# apollo2 register map
Vendor: Ambiq Micro; Series: Apollo; File version: 1.0
CPU: CM4 r1p0, little endian, MPU, FPU, 3 interrupt priority bits
Registers are 32-bit, read-write, reset 0x0 unless marked. A register's access mark holds for its fields unless they carry their own. Offsets are from the block's base; [hi:lo] are bit positions; 'fields as' and 'values as' point back to an identical list.

## RTC — Real Time Clock
Base 0x40004040
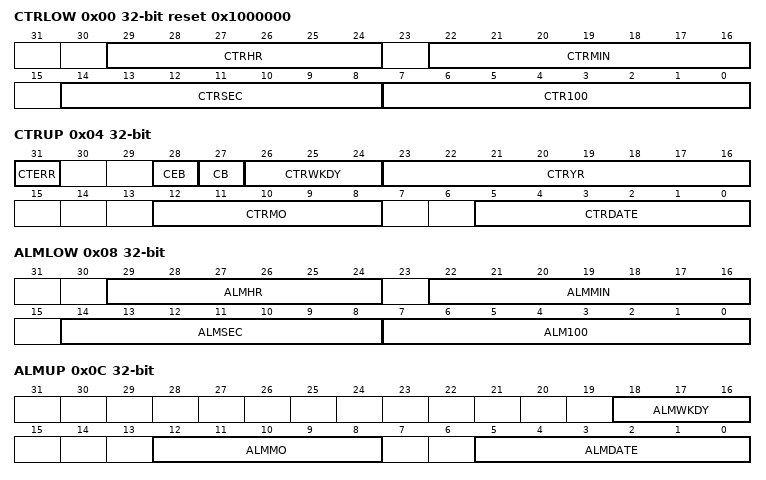
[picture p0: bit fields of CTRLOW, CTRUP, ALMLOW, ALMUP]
0x00 CTRLOW reset 0x1000000 — RTC Counters Lower
  [29:24] CTRHR — Hours Counter
  [22:16] CTRMIN — Minutes Counter
  [14:8] CTRSEC — Seconds Counter
  [7:0] CTR100 — 100ths of a second Counter
0x04 CTRUP — RTC Counters Upper
  [31] CTERR — Counter read error status
    0=NOERR (No read error occurred value.); 1=RDERR (Read error occurred value.)
  [28] CEB — Century enable
    0=DIS (Disable the Century bit from changing value.); 1=EN (Enable the Century bit to change value.)
  [27] CB — Century
    0=Century is 2000s value; 1=1900_2100 (Century is 1900s/2100s value.)
  [26:24] CTRWKDY — Weekdays Counter
  [23:16] CTRYR — Years Counter
  [12:8] CTRMO — Months Counter
  [5:0] CTRDATE — Date Counter
0x08 ALMLOW — RTC Alarms Lower
  [29:24] ALMHR — Hours Alarm
  [22:16] ALMMIN — Minutes Alarm
  [14:8] ALMSEC — Seconds Alarm
  [7:0] ALM100 — 100ths of a second Alarm
0x0C ALMUP — RTC Alarms Upper
  [18:16] ALMWKDY — Weekdays Alarm
  [12:8] ALMMO — Months Alarm
  [5:0] ALMDATE — Date Alarm
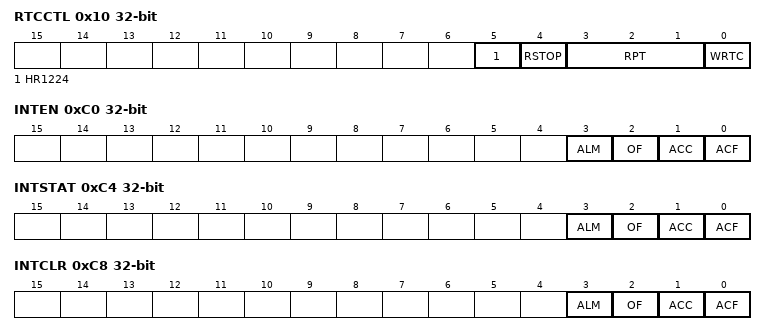
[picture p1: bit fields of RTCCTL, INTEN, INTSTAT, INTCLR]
0x10 RTCCTL — RTC Control Register
  [5] HR1224 — Hours Counter mode
    0=24HR (Hours in 24 hour mode value.); 1=12HR (Hours in 12 hour mode value.)
  [4] RSTOP — RTC input clock control
    0=RUN (Allow the RTC input clock to run value.); 1=STOP (Stop the RTC input clock value.)
  [3:1] RPT — Alarm repeat interval
    0=DIS (Alarm interrupt disabled value.); 1=YEAR (Interrupt every year value.); 2=MONTH (Interrupt every month value.); 3=WEEK (Interrupt every week value.); 4=DAY (Interrupt every day value.); 5=HR (Interrupt every hour value.); 6=MIN (Interrupt every minute value.); 7=SEC (Interrupt every second/10th/100th value.)
  [0] WRTC — Counter write control
    0=DIS (Counter writes are disabled value.); 1=EN (Counter writes are enabled value.)
0xC0 INTEN — RTC Interrupt Register: Enable
  [3] ALM — RTC Alarm interrupt
  [2] OF — XT Oscillator Fail interrupt
  [1] ACC — Autocalibration Complete interrupt
  [0] ACF — Autocalibration Fail interrupt
0xC4 INTSTAT — RTC Interrupt Register: Status
  fields as INTEN
0xC8 INTCLR — RTC Interrupt Register: Clear
  fields as INTEN
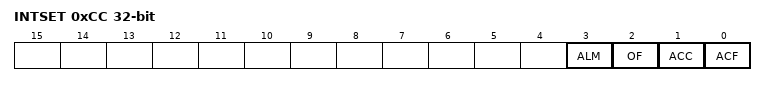
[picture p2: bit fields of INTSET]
0xCC INTSET — RTC Interrupt Register: Set
  fields as INTEN

## VCOMP — Voltage Comparator
Base 0x4000C000
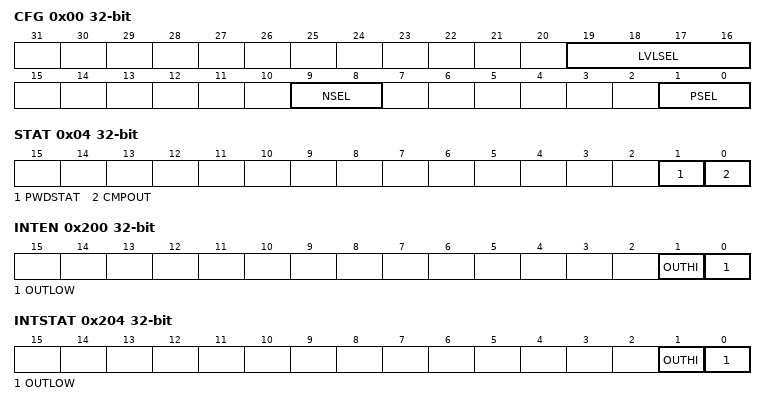
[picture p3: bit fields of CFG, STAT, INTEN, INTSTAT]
0x00 CFG — Configuration Register
  [19:16] LVLSEL — When the reference input NSEL is set to NSEL_DAC, this bitfield selects the voltage level for the negative input to the comparator.
    0=0P58V (Set Reference input to 0.58 Volts. value.); 1=0P77V (Set Reference input to 0.77 Volts. value.); 2=0P97V (Set Reference input to 0.97 Volts. value.); 3=1P16V (Set Reference input to 1.16 Volts. value.); 4=1P35V (Set Reference input to 1.35 Volts. value.); 5=1P55V (Set Reference input to 1.55 Volts. value.); 6=1P74V (Set Reference input to 1.74 Volts. value.); 7=1P93V (Set Reference input to 1.93 Volts. value.); 8=2P13V (Set Reference input to 2.13 Volts. value.); 9=2P32V (Set Reference input to 2.32 Volts. value.); 10=2P51V (Set Reference input to 2.51 Volts. value.); 11=2P71V (Set Reference input to 2.71 Volts. value.); 12=2P90V (Set Reference input to 2.90 Volts. value.); 13=3P09V (Set Reference input to 3.09 Volts. value.); 14=3P29V (Set Reference input to 3.29 Volts. value.); 15=3P48V (Set Reference input to 3.48 Volts. value.)
  [9:8] NSEL — This bitfield selects the negative input to the comparator.
    0=VREFEXT1 (Use external reference 1 for reference input. value.); 1=VREFEXT2 (Use external reference 2 for reference input. value.); 2=VREFEXT3 (Use external reference 3 for reference input. value.); 3=DAC (Use DAC output selected by LVLSEL for reference input. value.)
  [1:0] PSEL — This bitfield selects the positive input to the comparator.
    0=VDDADJ (Use VDDADJ for the positive input. value.); 1=VTEMP (Use the temperature sensor output for the positive input. Note: If this channel is selected for PSEL, the bandap circuit required for temperature comparisons will automatically turn on. The bandgap circuit requires 11us to stabalize. value.); 2=VEXT1 (Use external voltage 0 for positive input. value.); 3=VEXT2 (Use external voltage 1 for positive input. value.)
0x04 STAT — Status Register
  [1] PWDSTAT — This bit indicates the power down state of the voltage comparator.
    1=POWERED_DOWN (The voltage comparator is powered down. value.)
  [0] CMPOUT — This bit is 1 if the positive input of the comparator is greater than the negative input.
    0=VOUT_LOW (The negative input of the comparator is greater than the positive input. value.); 1=VOUT_HIGH (The positive input of the comparator is greater than the negative input. value.)
0x08 PWDKEY — Key Register for Powering Down the Voltage Comparator
  [31:0] PWDKEY — Key register value.
    55=Key (Key value.)
0x200 INTEN — Voltage Comparator Interrupt registers: Enable
  [1] OUTHI — This bit is the vcompout high interrupt.
  [0] OUTLOW — This bit is the vcompout low interrupt.
0x204 INTSTAT — Voltage Comparator Interrupt registers: Status
  fields as INTEN
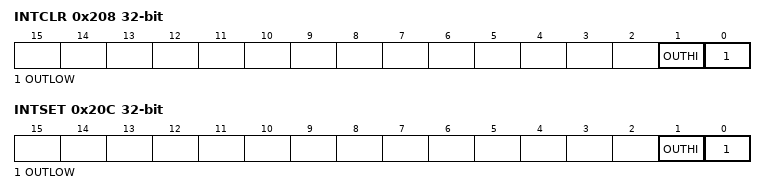
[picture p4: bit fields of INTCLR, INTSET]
0x208 INTCLR — Voltage Comparator Interrupt registers: Clear
  fields as INTEN
0x20C INTSET — Voltage Comparator Interrupt registers: Set
  fields as INTEN

## WDT — Watchdog Timer
Base 0x40024000
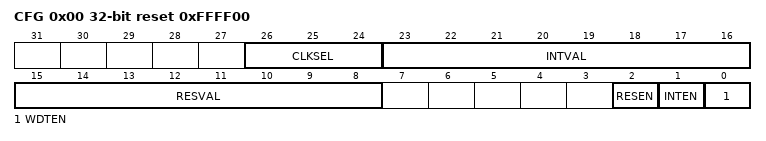
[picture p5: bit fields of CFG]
0x00 CFG reset 0xFFFF00 — Configuration Register
  [26:24] CLKSEL — Select the frequency for the WDT. All values not enumerated below are undefined.
    0=OFF (Low Power Mode. value.); 1=128HZ (128 Hz LFRC clock. value.); 2=16HZ (16 Hz LFRC clock. value.); 3=1HZ (1 Hz LFRC clock. value.); 4=1_16HZ (1/16th Hz LFRC clock. value.)
  [23:16] INTVAL — This bitfield is the compare value for counter bits 7:0 to generate a watchdog interrupt.
  [15:8] RESVAL — This bitfield is the compare value for counter bits 7:0 to generate a watchdog reset.
  [2] RESEN — This bitfield enables the WDT reset.
  [1] INTEN — This bitfield enables the WDT interrupt. Note : This bit must be set before the interrupt status bit will reflect a watchdog timer expiration. The IER interrupt register must also be enabled for a WDT interrupt to be sent to the NVIC.
  [0] WDTEN — This bitfield enables the WDT.
0x04 RSTRT — Restart the watchdog timer
  [7:0] RSTRT — Writing 0xB2 to WDTRSTRT restarts the watchdog timer.
    178=KEYVALUE (This is the key value to write to WDTRSTRT to restart the WDT. value.)
0x08 LOCK — Locks the WDT
  [7:0] LOCK — Writing 0x3A locks the watchdog timer. Once locked, the WDTCFG reg cannot be written and WDTEN is set.
    58=KEYVALUE (This is the key value to write to WDTLOCK to lock the WDT. value.)
0x0C COUNT — Current Counter Value for WDT
  [7:0] COUNT — Read-Only current value of the WDT counter
0x200 INTEN — WDT Interrupt register: Enable
  [0] WDTINT — Watchdog Timer Interrupt.
0x204 INTSTAT — WDT Interrupt register: Status
  [0] WDTINT — Watchdog Timer Interrupt.
0x208 INTCLR — WDT Interrupt register: Clear
  [0] WDTINT — Watchdog Timer Interrupt.
0x20C INTSET — WDT Interrupt register: Set
  [0] WDTINT — Watchdog Timer Interrupt.
